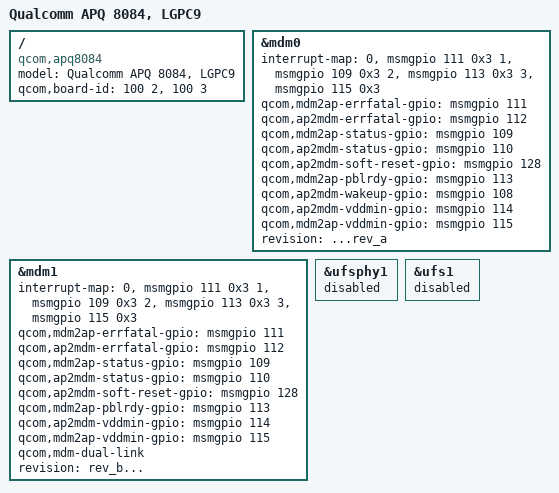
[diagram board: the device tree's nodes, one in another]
/* Copyright (c) 2013-2014, The Linux Foundation. All rights reserved.
 *
 * This program is free software; you can redistribute it and/or modify
 * it under the terms of the GNU General Public License version 2 and
 * only version 2 as published by the Free Software Foundation.
 *
 * This program is distributed in the hope that it will be useful,
 * but WITHOUT ANY WARRANTY; without even the implied warranty of
 * MERCHANTABILITY or FITNESS FOR A PARTICULAR PURPOSE.  See the
 * GNU General Public License for more details.
 */

/dts-v1/;

#include "../apq8084-lge-common/apq8084-lge.dtsi"
#include "apq8084-lgpc9.dtsi"

/ {
	model = "Qualcomm APQ 8084, LGPC9";
	compatible = "qcom,apq8084";
	qcom,board-id = <100 2>,
			<100 3>;
};

&mdm0 {
	interrupt-map = <0 &msmgpio 111 0x3
			1 &msmgpio 109 0x3
			2 &msmgpio 113 0x3
			3 &msmgpio 115 0x3>;
	qcom,mdm2ap-errfatal-gpio = <&msmgpio 111 0x00>;
	qcom,ap2mdm-errfatal-gpio = <&msmgpio 112 0x00>;
	qcom,mdm2ap-status-gpio   = <&msmgpio 109 0x00>;
	qcom,ap2mdm-status-gpio   = <&msmgpio 110 0x00>;
	qcom,ap2mdm-soft-reset-gpio = <&msmgpio 128 0x00>;
	qcom,mdm2ap-pblrdy-gpio = <&msmgpio 113 0x00>;
	qcom,ap2mdm-wakeup-gpio = <&msmgpio 108 0x00>;
	qcom,ap2mdm-vddmin-gpio = <&msmgpio 114 0x00>;
	qcom,mdm2ap-vddmin-gpio = <&msmgpio 115 0x00>;
	revision = "...rev_a";
	status = "ok";
};

&mdm1 {
	interrupt-map = <0 &msmgpio 111 0x3
			1 &msmgpio 109 0x3
			2 &msmgpio 113 0x3
			3 &msmgpio 115 0x3>;
	qcom,mdm2ap-errfatal-gpio = <&msmgpio 111 0x00>;
	qcom,ap2mdm-errfatal-gpio = <&msmgpio 112 0x00>;
	qcom,mdm2ap-status-gpio   = <&msmgpio 109 0x00>;
	qcom,ap2mdm-status-gpio   = <&msmgpio 110 0x00>;
	qcom,ap2mdm-soft-reset-gpio = <&msmgpio 128 0x00>;
	qcom,mdm2ap-pblrdy-gpio = <&msmgpio 113 0x00>;
	qcom,ap2mdm-vddmin-gpio = <&msmgpio 114 0x00>;
	qcom,mdm2ap-vddmin-gpio = <&msmgpio 115 0x00>;
	qcom,mdm-dual-link;
	revision = "rev_b...";
	status = "ok";
};

&ufsphy1 {
	status = "disabled";
};

&ufs1 {
	status = "disabled";
};
